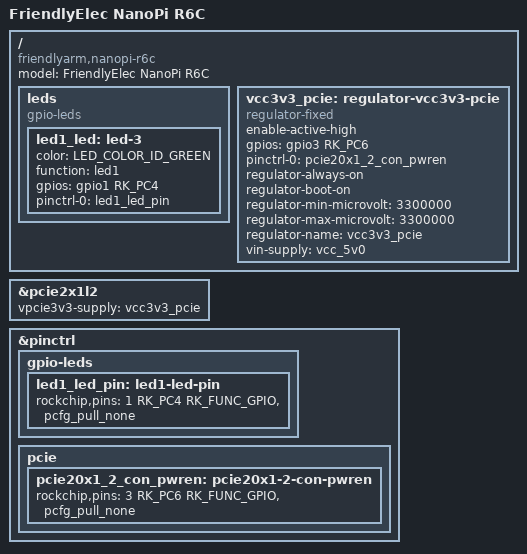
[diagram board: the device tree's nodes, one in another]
// SPDX-License-Identifier: (GPL-2.0+ OR MIT)

/dts-v1/;

#include "rk3588s-nanopi-r6.dtsi"

/ {
	model = "FriendlyElec NanoPi R6C";
	compatible = "friendlyarm,nanopi-r6c", "rockchip,rk3588s";

	leds {
		compatible = "gpio-leds";

		led1_led: led-3 {
			color = <LED_COLOR_ID_GREEN>;
			function = "led1";
			gpios = <&gpio1 RK_PC4 GPIO_ACTIVE_HIGH>;
			pinctrl-names = "default";
			pinctrl-0 = <&led1_led_pin>;
		};
	};

	/* MP2143DJ power switch (U9536 in schematics) */
	vcc3v3_pcie: regulator-vcc3v3-pcie {
		compatible = "regulator-fixed";
		enable-active-high;
		gpios = <&gpio3 RK_PC6 GPIO_ACTIVE_HIGH>;
		pinctrl-names = "default";
		pinctrl-0 = <&pcie20x1_2_con_pwren>;
		regulator-always-on;
		regulator-boot-on;
		regulator-min-microvolt = <3300000>;
		regulator-max-microvolt = <3300000>;
		regulator-name = "vcc3v3_pcie";
		vin-supply = <&vcc_5v0>;
	};
};

/* M.2 M-Key socket */
&pcie2x1l2 {
	vpcie3v3-supply = <&vcc3v3_pcie>;
};

&pinctrl {
	gpio-leds {
		led1_led_pin: led1-led-pin {
			rockchip,pins = <1 RK_PC4 RK_FUNC_GPIO &pcfg_pull_none>;
		};
	};

	pcie {
		pcie20x1_2_con_pwren: pcie20x1-2-con-pwren {
			rockchip,pins = <3 RK_PC6 RK_FUNC_GPIO &pcfg_pull_none>;
		};
	};
};
